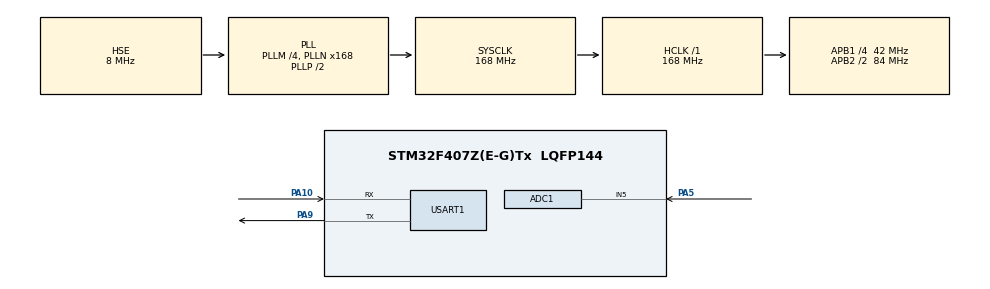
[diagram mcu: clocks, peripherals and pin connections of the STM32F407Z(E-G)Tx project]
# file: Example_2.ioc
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ADC1.Channel-0\#ChannelRegularConversion=ADC_CHANNEL_5
ADC1.ExternalTrigConv=ADC_EXTERNALTRIGCONV_T3_TRGO
ADC1.NbrOfConversionFlag=1
ADC1.Rank-0\#ChannelRegularConversion=1
ADC1.SamplingTime-0\#ChannelRegularConversion=ADC_SAMPLETIME_15CYCLES
ADC1.master=1
FREERTOS.Tasks01=task_ADC,24,128,TASK_ADC,Default,NULL,Dynamic,NULL,NULL
FREERTOS.configTICK_RATE_HZ=1000
FREERTOS.configUSE_IDLE_HOOK=0
Mcu.Family=STM32F4
Mcu.Name=STM32F407Z(E-G)Tx
Mcu.Package=LQFP144
NVIC.ADC_IRQn=true\:7\:0\:true\:false\:true\:true\:true\:true\:true
NVIC.PriorityGroup=NVIC_PRIORITYGROUP_4
NVIC.TIM6_DAC_IRQn=true\:15\:0\:true\:false\:true\:false\:false\:true\:true
NVIC.TimeBase=TIM6_DAC_IRQn
NVIC.TimeBaseIP=TIM6
PA10.Mode=Asynchronous
PA10.Signal=USART1_RX
PA13.Mode=Serial_Wire
PA13.Signal=SYS_JTMS-SWDIO
PA14.Mode=Serial_Wire
PA14.Signal=SYS_JTCK-SWCLK
PA5.Signal=ADCx_IN5
PA9.Mode=Asynchronous
PA9.Signal=USART1_TX
PC14-OSC32_IN.Mode=LSE-External-Oscillator
PC14-OSC32_IN.Signal=RCC_OSC32_IN
PC15-OSC32_OUT.Mode=LSE-External-Oscillator
PC15-OSC32_OUT.Signal=RCC_OSC32_OUT
PH0-OSC_IN.Mode=HSE-External-Oscillator
PH0-OSC_IN.Signal=RCC_OSC_IN
PH1-OSC_OUT.Mode=HSE-External-Oscillator
PH1-OSC_OUT.Signal=RCC_OSC_OUT
ProjectManager.HeapSize=0x200
ProjectManager.StackSize=0x400
ProjectManager.TargetToolchain=MDK-ARM V5.32
RCC.48MHZClocksFreq_Value=84000000
RCC.AHBFreq_Value=168000000
RCC.APB1CLKDivider=RCC_HCLK_DIV4
RCC.APB1Freq_Value=42000000
RCC.APB1TimFreq_Value=84000000
RCC.APB2CLKDivider=RCC_HCLK_DIV2
RCC.APB2Freq_Value=84000000
RCC.APB2TimFreq_Value=168000000
RCC.CortexFreq_Value=168000000
RCC.HCLKFreq_Value=168000000
RCC.HSE_VALUE=8000000
RCC.HSI_VALUE=16000000
RCC.PLLM=4
RCC.PLLN=168
RCC.PLLSourceVirtual=RCC_PLLSOURCE_HSE
RCC.RCC_RTC_Clock_Source=RCC_RTCCLKSOURCE_LSE
RCC.RCC_RTC_Clock_SourceVirtual=RCC_RTCCLKSOURCE_LSE
RCC.SYSCLKFreq_VALUE=168000000
RCC.SYSCLKSource=RCC_SYSCLKSOURCE_PLLCLK
RCC.VCOOutputFreq_Value=336000000
SH.ADCx_IN5.0=ADC1_IN5,IN5
TIM3.Period=4999
TIM3.Prescaler=8399
TIM3.TIM_MasterOutputTrigger=TIM_TRGO_UPDATE
USART1.VirtualMode=VM_ASYNC
VP_FREERTOS_VS_CMSIS_V2.Mode=CMSIS_V2
VP_SYS_VS_tim6.Mode=TIM6
VP_TIM3_VS_ClockSourceINT.Mode=Internal
board=custom

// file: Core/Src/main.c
/* USER CODE BEGIN Header */
/**
  ******************************************************************************
  * @file           : main.c
  * @brief          : Main program body
  ******************************************************************************
  * @attention
  *
  * Copyright (c) 2024 STMicroelectronics.
  * All rights reserved.
  *
  * This software is licensed under terms that can be found in the LICENSE file
  * in the root directory of this software component.
  * If no LICENSE file comes with this software, it is provided AS-IS.
  *
  ******************************************************************************
  */
/* USER CODE END Header */
#include "main.h"
#include "cmsis_os.h"
#include "adc.h"
#include "tim.h"
#include "usart.h"
#include "gpio.h"

/* USER CODE BEGIN Includes */
#include "stdio.h"

#ifdef __GNUC__
#define PUTCHAR_PROTOTYPE int __io_putchar(int ch)
#else
#define PUTCHAR_PROTOTYPE int fputc(int ch, FILE *f)
#endif
PUTCHAR_PROTOTYPE
{
    HAL_UART_Transmit(&huart1, (uint8_t *)&ch, 1, HAL_MAX_DELAY);
    return ch;
}
/* USER CODE END Includes */

void SystemClock_Config(void);
void MX_FREERTOS_Init(void);

int main(void)
{

  /* MCU Configuration--------------------------------------------------------*/

  /* Reset of all peripherals, Initializes the Flash interface and the Systick. */
  HAL_Init();

  /* Configure the system clock */
  SystemClock_Config();

  /* Initialize all configured peripherals */
  MX_GPIO_Init();
  MX_USART1_UART_Init();
  MX_ADC1_Init();
  MX_TIM3_Init();
  /* USER CODE BEGIN 2 */
	HAL_ADC_Start_IT(&hadc1);
	HAL_TIM_Base_Start(&htim3);
  /* USER CODE END 2 */

  /* Init scheduler */
  osKernelInitialize();

  /* Call init function for freertos objects (in freertos.c) */
  MX_FREERTOS_Init();

  /* Start scheduler */
  osKernelStart();

  /* We should never get here as control is now taken by the scheduler */
  /* Infinite loop */
  while (1)
  {

  }
}

void SystemClock_Config(void)
{
  RCC_OscInitTypeDef RCC_OscInitStruct = {0};
  RCC_ClkInitTypeDef RCC_ClkInitStruct = {0};

  /** Configure the main internal regulator output voltage
  */
  __HAL_RCC_PWR_CLK_ENABLE();
  __HAL_PWR_VOLTAGESCALING_CONFIG(PWR_REGULATOR_VOLTAGE_SCALE1);

  /** Initializes the RCC Oscillators according to the specified parameters
  * in the RCC_OscInitTypeDef structure.
  */
  RCC_OscInitStruct.OscillatorType = RCC_OSCILLATORTYPE_HSE;
  RCC_OscInitStruct.HSEState = RCC_HSE_ON;
  RCC_OscInitStruct.PLL.PLLState = RCC_PLL_ON;
  RCC_OscInitStruct.PLL.PLLSource = RCC_PLLSOURCE_HSE;
  RCC_OscInitStruct.PLL.PLLM = 4;
  RCC_OscInitStruct.PLL.PLLN = 168;
  RCC_OscInitStruct.PLL.PLLP = RCC_PLLP_DIV2;
  RCC_OscInitStruct.PLL.PLLQ = 4;
  if (HAL_RCC_OscConfig(&RCC_OscInitStruct) != HAL_OK)
  {
    Error_Handler();
  }

  /** Initializes the CPU, AHB and APB buses clocks
  */
  RCC_ClkInitStruct.ClockType = RCC_CLOCKTYPE_HCLK|RCC_CLOCKTYPE_SYSCLK
                              |RCC_CLOCKTYPE_PCLK1|RCC_CLOCKTYPE_PCLK2;
  RCC_ClkInitStruct.SYSCLKSource = RCC_SYSCLKSOURCE_PLLCLK;
  RCC_ClkInitStruct.AHBCLKDivider = RCC_SYSCLK_DIV1;
  RCC_ClkInitStruct.APB1CLKDivider = RCC_HCLK_DIV4;
  RCC_ClkInitStruct.APB2CLKDivider = RCC_HCLK_DIV2;

  if (HAL_RCC_ClockConfig(&RCC_ClkInitStruct, FLASH_LATENCY_5) != HAL_OK)
  {
    Error_Handler();
  }
}

void HAL_TIM_PeriodElapsedCallback(TIM_HandleTypeDef *htim)
{
  if (htim->Instance == TIM6) {
    HAL_IncTick();
  }
}

void Error_Handler(void)
{
  __disable_irq();
  while (1)
  {
  }
}

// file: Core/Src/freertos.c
/* USER CODE BEGIN Header */
/**
  ******************************************************************************
  * File Name          : freertos.c
  * Description        : Code for freertos applications
  ******************************************************************************
  * @attention
  *
  * Copyright (c) 2024 STMicroelectronics.
  * All rights reserved.
  *
  * This software is licensed under terms that can be found in the LICENSE file
  * in the root directory of this software component.
  * If no LICENSE file comes with this software, it is provided AS-IS.
  *
  ******************************************************************************
  */
/* USER CODE END Header */

#include "FreeRTOS.h"
#include "task.h"
#include "main.h"
#include "cmsis_os.h"

/* USER CODE BEGIN Includes */
#include "stdio.h"
/* USER CODE END Includes */

/* Definitions for task_ADC */
osThreadId_t task_ADCHandle;
const osThreadAttr_t task_ADC_attributes = {
  .name = "task_ADC",
  .stack_size = 128 * 4,
  .priority = (osPriority_t) osPriorityNormal,
};

void TASK_ADC(void *argument);

void MX_FREERTOS_Init(void); /* (MISRA C 2004 rule 8.1) */

void MX_FREERTOS_Init(void) {

  /* Create the thread(s) */
  /* creation of task_ADC */
  task_ADCHandle = osThreadNew(TASK_ADC, NULL, &task_ADC_attributes);

}

void TASK_ADC(void *argument)
{
  /* USER CODE BEGIN TASK_ADC */
	//定义一个变量用于表示任务待处理的事件数量
	uint32_t notifyValue;
  /* Infinite loop */
  for(;;)
  {
		uint32_t ulBitsToClearOnEntry = 0x00;
		uint32_t ulBitsToClearOnExit = 0xFFFFFFFF;
		//等待任务通知
		BaseType_t result = xTaskNotifyWait(ulBitsToClearOnEntry, ulBitsToClearOnExit ,&notifyValue ,portMAX_DELAY);
		//如果等到事件
		if(result == pdTRUE)
		{
			uint32_t Volt = (3300 * notifyValue)>>12;
			printf("val:%d, Volt:%d\r\n", notifyValue, Volt);
		}
	}
  /* USER CODE END TASK_ADC */
}

/* USER CODE BEGIN Application */
/*ADC转换完成中断回调*/
void HAL_ADC_ConvCpltCallback(ADC_HandleTypeDef *hadc)
{
	//定时器中断启动单通道转换
	if(hadc->Instance == ADC1)
	{
		//获取原始ADC采集值
		uint32_t adc_value = HAL_ADC_GetValue(hadc);
		BaseType_t highTaskWoken = pdFALSE;
		if(task_ADCHandle != NULL)
		{
			//采集完毕给TASK_ADC任务发送采集完毕的通知
			xTaskNotifyFromISR(task_ADCHandle,adc_value ,eSetValueWithOverwrite ,&highTaskWoken);
			portYIELD_FROM_ISR(highTaskWoken);
		}
	}
}
/* USER CODE END Application */
